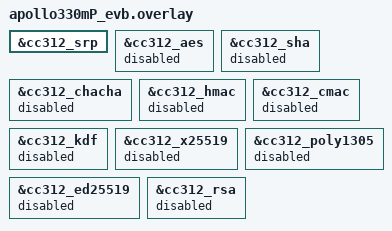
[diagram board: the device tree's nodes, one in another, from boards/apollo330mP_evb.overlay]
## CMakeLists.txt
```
# Copyright (c) 2026 Ambiq Micro, Inc.
# SPDX-License-Identifier: Apache-2.0

cmake_minimum_required(VERSION 3.20.0)

find_package(Zephyr REQUIRED HINTS $ENV{ZEPHYR_BASE})
project(srp_hal_example)

target_sources(app PRIVATE src/main.c)
```

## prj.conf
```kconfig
# Copyright (c) 2026 Ambiq Micro, Inc.
# SPDX-License-Identifier: Apache-2.0

CONFIG_CONSOLE=y
CONFIG_SERIAL=y
CONFIG_PRINTK=y
CONFIG_CRYPTO=y
CONFIG_CRYPTO_AMBIQ_SRP=y
CONFIG_NOCACHE_MEMORY=y
CONFIG_MAIN_STACK_SIZE=16384
```

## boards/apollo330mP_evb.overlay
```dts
/*
 * Copyright (c) 2026 Ambiq Micro, Inc.
 * SPDX-License-Identifier: Apache-2.0
 */

&cc312_srp {
	status = "okay";
};

&cc312_aes {
	status = "disabled";
};

&cc312_sha {
	status = "disabled";
};

&cc312_chacha {
	status = "disabled";
};

&cc312_hmac {
	status = "disabled";
};

&cc312_cmac {
	status = "disabled";
};

&cc312_kdf {
	status = "disabled";
};

&cc312_x25519 {
	status = "disabled";
};

&cc312_poly1305 {
	status = "disabled";
};

&cc312_ed25519 {
	status = "disabled";
};

&cc312_rsa {
	status = "disabled";
};
```

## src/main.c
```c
/*
 * Copyright (c) 2026 Ambiq Micro, Inc.
 *
 * SPDX-License-Identifier: Apache-2.0
 */

#include <zephyr/device.h>
#include <zephyr/drivers/crypto/crypto_ambiq_srp.h>
#include <zephyr/kernel.h>
#include <zephyr/linker/section_tags.h>
#include <zephyr/sys/printk.h>

#include <string.h>

#include <soc.h>

#define SRP_DEV DEVICE_DT_GET_ONE(ambiq_crypto_srp)

#define SRP_MOD_BYTES 128U

#if IS_ENABLED(CONFIG_NOCACHE_MEMORY)
#define SRP_NOCACHE __nocache
#else
#define SRP_NOCACHE
#endif

static SRP_NOCACHE uint8_t g_k[32] __aligned(32);
static SRP_NOCACHE uint8_t g_v[SRP_MOD_BYTES] __aligned(32);

/* RFC 5054 Appendix A.1 1024-bit group (SHA-256 for k / verifier) */
static const uint8_t modulus[SRP_MOD_BYTES] = {
	0xee, 0xaf, 0x0a, 0xb9, 0xad, 0xb3, 0x8d, 0xd6, 0x9c, 0x33, 0xf8, 0x0a, 0xfa, 0x8f, 0xc5,
	0xe8, 0x60, 0x72, 0x61, 0x87, 0x75, 0xff, 0x3c, 0x0b, 0x9e, 0xa2, 0x31, 0x4c, 0x9c, 0x25,
	0x65, 0x76, 0xd6, 0x74, 0xdf, 0x74, 0x96, 0xea, 0x81, 0xd3, 0x38, 0x3b, 0x48, 0x13, 0xd6,
	0x92, 0xc6, 0xe0, 0xe0, 0xd5, 0xd8, 0xe2, 0x50, 0xb9, 0x8b, 0xe4, 0x8e, 0x49, 0x5c, 0x1d,
	0x60, 0x89, 0xda, 0xd1, 0x5d, 0xc7, 0xd7, 0xb4, 0x61, 0x54, 0xd6, 0xb6, 0xce, 0x8e, 0xf4,
	0xad, 0x69, 0xb1, 0x5d, 0x49, 0x82, 0x55, 0x9b, 0x29, 0x7b, 0xcf, 0x18, 0x85, 0xc5, 0x29,
	0xf5, 0x66, 0x66, 0x0e, 0x57, 0xec, 0x68, 0xed, 0xbc, 0x3c, 0x05, 0x72, 0x6c, 0xc0, 0x2f,
	0xd4, 0xcb, 0xf4, 0x97, 0x6e, 0xaa, 0x9a, 0xfd, 0x51, 0x38, 0xfe, 0x83, 0x76, 0x43, 0x5b,
	0x9f, 0xc6, 0x1d, 0x2f, 0xc0, 0xeb, 0x06, 0xe3,
};

/* PAD(g): g = 2 as a big-endian integer the width of N */
static const uint8_t generator[SRP_MOD_BYTES] = {
	0x00, 0x00, 0x00, 0x00, 0x00, 0x00, 0x00, 0x00, 0x00, 0x00, 0x00, 0x00, 0x00, 0x00, 0x00,
	0x00, 0x00, 0x00, 0x00, 0x00, 0x00, 0x00, 0x00, 0x00, 0x00, 0x00, 0x00, 0x00, 0x00, 0x00,
	0x00, 0x00, 0x00, 0x00, 0x00, 0x00, 0x00, 0x00, 0x00, 0x00, 0x00, 0x00, 0x00, 0x00, 0x00,
	0x00, 0x00, 0x00, 0x00, 0x00, 0x00, 0x00, 0x00, 0x00, 0x00, 0x00, 0x00, 0x00, 0x00, 0x00,
	0x00, 0x00, 0x00, 0x00, 0x00, 0x00, 0x00, 0x00, 0x00, 0x00, 0x00, 0x00, 0x00, 0x00, 0x00,
	0x00, 0x00, 0x00, 0x00, 0x00, 0x00, 0x00, 0x00, 0x00, 0x00, 0x00, 0x00, 0x00, 0x00, 0x00,
	0x00, 0x00, 0x00, 0x00, 0x00, 0x00, 0x00, 0x00, 0x00, 0x00, 0x00, 0x00, 0x00, 0x00, 0x00,
	0x00, 0x00, 0x00, 0x00, 0x00, 0x00, 0x00, 0x00, 0x00, 0x00, 0x00, 0x00, 0x00, 0x00, 0x00,
	0x00, 0x00, 0x00, 0x00, 0x00, 0x00, 0x00, 0x02,
};

/* k = SHA-256(N || PAD(g)) */
static const uint8_t k_exp[32] = {
	0x1a, 0x1a, 0x4c, 0x14, 0x0c, 0xde, 0x70, 0xae, 0x36, 0x0c, 0x1e,
	0xc3, 0x3a, 0x33, 0x15, 0x5b, 0x10, 0x22, 0xdf, 0x95, 0x17, 0x32,
	0xa4, 0x76, 0xa8, 0x62, 0xeb, 0x3a, 0xb8, 0x20, 0x6a, 0x5c,
};

/* x = H(salt || H("alice:password123")) with salt 0xBE17 */
static const uint8_t x_val[32] = {
	0x28, 0x5a, 0x39, 0xa8, 0xb6, 0x78, 0xad, 0xc1, 0x04, 0x17, 0x84,
	0x78, 0xe6, 0x81, 0x65, 0x60, 0x3b, 0x2c, 0x95, 0x91, 0x12, 0xb8,
	0xad, 0xf8, 0x66, 0x18, 0x69, 0x5b, 0xfd, 0x93, 0x3f, 0xaa,
};

/* v = g^x mod N */
static const uint8_t v_exp[SRP_MOD_BYTES] = {
	0x59, 0xdd, 0xf6, 0xbf, 0x06, 0xfc, 0x20, 0xe0, 0x74, 0x7f, 0x72, 0xa3, 0x2c, 0x6a, 0xff,
	0x5d, 0xa2, 0x67, 0xc7, 0xa5, 0x70, 0xa3, 0x18, 0x27, 0x1d, 0x14, 0x3a, 0x5a, 0x42, 0x80,
	0x2a, 0xbd, 0x9c, 0xfb, 0x93, 0xa4, 0x5e, 0x8b, 0x07, 0x95, 0xb1, 0x4f, 0x1c, 0x94, 0x44,
	0x5d, 0x65, 0xf9, 0xf5, 0xec, 0x4a, 0xad, 0xac, 0x0f, 0xb6, 0x4e, 0x1e, 0x99, 0x08, 0x6b,
	0x7f, 0x6b, 0x85, 0x1d, 0x4d, 0x02, 0x9d, 0x98, 0xb2, 0x4e, 0xb9, 0x33, 0x66, 0x3c, 0x55,
	0x2e, 0xfe, 0x66, 0xa7, 0xe9, 0x2e, 0xb8, 0x46, 0xad, 0x31, 0x11, 0x44, 0x23, 0xa1, 0xa0,
	0xd9, 0x48, 0xdb, 0xbd, 0x83, 0x4e, 0xd5, 0xe3, 0xa5, 0x71, 0x51, 0xac, 0x2c, 0xfc, 0xc6,
	0xcf, 0xd4, 0xee, 0x86, 0xf7, 0x90, 0xf6, 0xef, 0x7a, 0x25, 0xf6, 0xd5, 0xe9, 0xa3, 0x65,
	0x5a, 0x7e, 0xdb, 0x7b, 0x3b, 0xeb, 0x89, 0x88,
};

static const struct crypto_ambiq_srp_group srp_group = {
	.n = modulus,
	.g = generator,
	.modulus_bytes = SRP_MOD_BYTES,
	.hash = CRYPTO_HASH_ALGO_SHA256,
};

int main(void)
{
	const struct device *dev = SRP_DEV;
	const struct crypto_ambiq_srp_driver_api *api;
	int ret;
	bool ok_k;
	bool ok_v;

	printk("\nAmbiq CC312 SRP driver checks\n\n");

	if (!device_is_ready(dev)) {
		printk("SRP device not ready\n");
		return 0;
	}

	api = (const struct crypto_ambiq_srp_driver_api *)dev->api;

	am_hal_cc312_context_clear(g_k, sizeof(g_k));
	ret = api->derive_k(dev, &srp_group, g_k);
	ok_k = (ret == 0) && (memcmp(g_k, k_exp, sizeof(k_exp)) == 0);
	printk("SRP derive_k (RFC5054 1024-bit)          %s\n", ok_k ? "PASS" : "FAIL");

	am_hal_cc312_context_clear(g_v, sizeof(g_v));
	ret = crypto_ambiq_srp_derive_verifier(dev, &srp_group, x_val, sizeof(x_val), g_v);
	ok_v = (ret == 0) && (memcmp(g_v, v_exp, sizeof(v_exp)) == 0);
	printk("SRP derive_verifier                    %s\n", ok_v ? "PASS" : "FAIL");

	if (ok_k && ok_v) {
		printk("All driver checks passed\n");
	}

	return 0;
}
```
